# RN821X_RN721X_SOC_V3 register map
File version: v1.0.4
CPU: CM0 r0p0, little endian, no MPU, no FPU, 3 interrupt priority bits
Registers are 32-bit, read-write, reset 0x0 unless marked. A register's access mark holds for its fields unless they carry their own. Offsets are from the block's base; [hi:lo] are bit positions; {n}, {i} and the like mark numbered series.

## UART0 — UART tranceiver
Base 0x40000000
Same registers: UART1 0x40004000, UART2 0x40008000, UART3 0x4000C000, UART4 0x40018000, UART5 0x4001C000
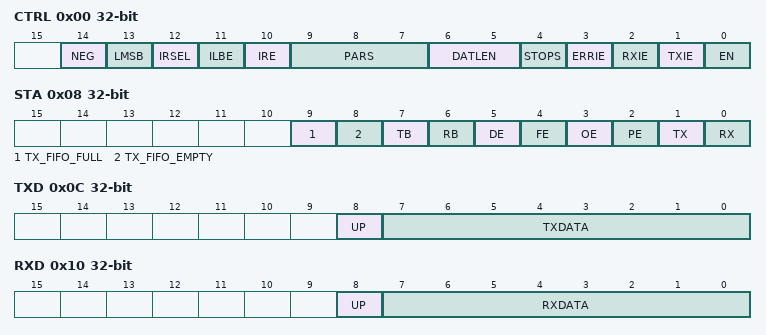
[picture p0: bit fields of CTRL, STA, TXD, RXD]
0x00 CTRL — UART control register
  [14] NEG — UART transfer polarity selection bit
    0=P (positive polarity (default driving voltage is high)); 1=N (negative polarity (default driving voltage is low))
  [13] LMSB — LSB/MSB transfer mode selection
    0=L (LSB first transfer mode); 1=M (MSB first transfer mode)
  [12] IRSEL — infra-red modulation polarity selection bit
    0=P (positive polarity. default driving voltage is high); 1=N (negative polarity. default driving voltage is low)
  [11] ILBE — inner loopback enable bit
  [10] IRE — infra-red modulation enable bit
  [9:7] PARS — parity type selection bits
    0=NUL (parity type select no parity); 1=ODD (parity type select odd parity); 2=EVEN (parity type select even parity); 3=parity type select stick_zero parity; 4=parity type select stick one parity; 5=USER (parity type select user_defined parity)
  [6:5] DATLEN — data length of frame format Configuration bits
    {v}=select {v+5} bits of data field (v=0..3)
  [4] STOPS — stop bits width selection bit
    1=2BIT (stop bit_width select as 2 bit); 0=1BIT (stop bit_width select as 1 bit)
  [3] ERRIE — error interrupt enable bit
  [2] RXIE — receive interrupt enable bit
  [1] TXIE — transmit interrupt enable bit
  [0] EN — UART module enable bit
0x04 BAUD — UART baud rate configuration register
  [12:0] CLKDIV — baud rate configuration bits
0x08 STA — UART status register
  [9] TX_FIFO_FULL — transmit fifo full flag
  [8] TX_FIFO_EMPTY — transmit fifo empty flag
  [7] TB — transmit busy flag
  [6] RB — receive busy flag
  [5] DE write-1-clears — data error flag
  [4] FE write-1-clears — frame error flag
  [3] OE write-1-clears — overflow error flag
  [2] PE write-1-clears — parity error flag
  [1] TX write-1-clears — transmit finish flag
  [0] RX write-1-clears — receive finish flag
0x0C TXD — UART transmit data register
  [8] UP — User-defined parity bit(valid when user-defined parity selected)
  [7:0] TXDATA — Transmit data value
0x10 RXD — UART receive data register
  [8] UP ro — user-defined parity bit(valid when user-defined parity selected)
  [7:0] RXDATA ro — Received data value bits
0x14 FDIV — baud rate fractional part
  [13:0] FDIV — baud rate fractional divisor configuration bits
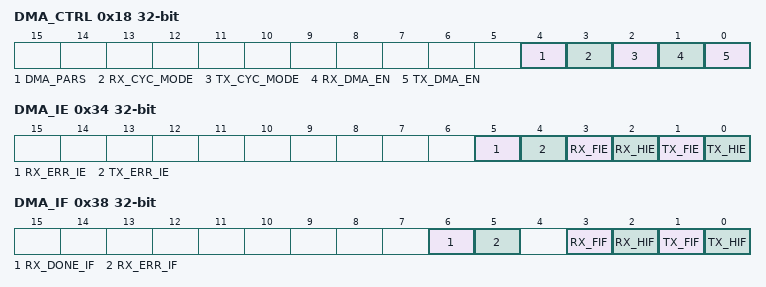
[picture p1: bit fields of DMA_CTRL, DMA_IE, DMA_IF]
0x18 DMA_CTRL — UART DMA control register
  [4] DMA_PARS — UART DMA parity bit
  [3] RX_CYC_MODE — UART RX loop mode enable bit
  [2] TX_CYC_MODE — UART TX loop mode enable bit
  [1] RX_DMA_EN — UART RX DMA enable bit
  [0] TX_DMA_EN — UART TX DMA enable bit
0x1C DMA_TBADR — UART DMA TX base address register
  [14:0] DMA_TBADR — UART DMA TX base address
0x20 DMA_RBADR — UART DMA RX base address register
  [14:0] DMA_RBADR — UART DMA RX base address
0x24 DMA_TLEN — UART DMA TX length register
  [14:0] DMA_TLEN — UART DMA TX length
0x28 DMA_RLEN — UART DMA RX length register
  [14:0] DMA_RLEN — UART DMA RX length
0x2C DMA_TADR — UART DMA TX current address register
  [14:0] DMA_TADR — UART DMA TX current address
0x30 DMA_RADR — UART DMA RX current address register
  [14:0] DMA_RADR — UART DMA RX current address
0x34 DMA_IE — UART DMA interrupt enable register
  [5] RX_ERR_IE — DMA RX error interrupt enable bit
  [4] TX_ERR_IE — DMA TX error interrupt enable bit
  [3] RX_FIE — DMA RX full interrupt enable bit
  [2] RX_HIE — DMA RX half-full interrupt enable bit
  [1] TX_FIE — DMA TX empty interrupt enable bit
  [0] TX_HIE — DMA TX half-full interrupt enable bit
0x38 DMA_IF — UART DMA interrupt flag register
  [6] RX_DONE_IF write-1-clears — DMA RX done interrupt flag
  [5] RX_ERR_IF write-1-clears — DMA RX error interrupt flag
  [3] RX_FIF write-1-clears — DMA RX full interrupt flag
  [2] RX_HIF write-1-clears — DMA RX half-full interrupt flag
  [1] TX_FIF write-1-clears — DMA TX empty interrupt flag
  [0] TX_HIF write-1-clears — DMA TX half-full interrupt flag
0x3C DMA_TO — UART DMA Time out configuration register
  [3:0] DMA_TO — DMA time out counter data bits
